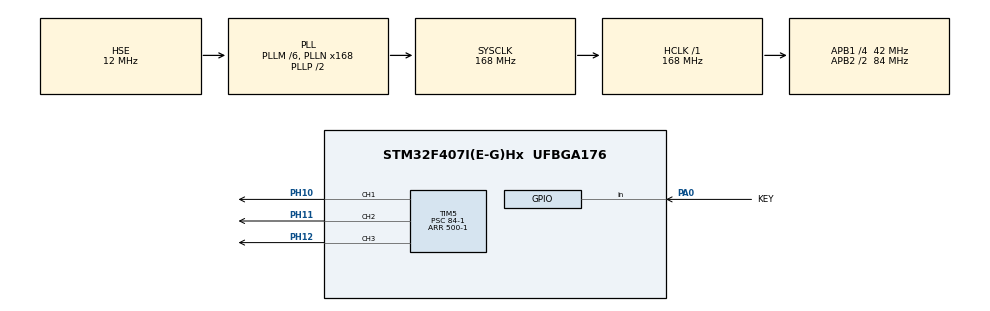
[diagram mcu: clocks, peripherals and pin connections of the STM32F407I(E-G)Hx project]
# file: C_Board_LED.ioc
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FREERTOS.Tasks01=LedTask,24,128,StartLedTask,Default,NULL,Dynamic,NULL,NULL
Mcu.Family=STM32F4
Mcu.Name=STM32F407I(E-G)Hx
Mcu.Package=UFBGA176
NVIC.PriorityGroup=NVIC_PRIORITYGROUP_4
NVIC.TIM4_IRQn=true\:15\:0\:false\:false\:true\:false\:false\:true\:true
NVIC.TimeBase=TIM4_IRQn
NVIC.TimeBaseIP=TIM4
PA0-WKUP.GPIO_Label=KEY
PA0-WKUP.GPIO_PuPd=GPIO_NOPULL
PA0-WKUP.Signal=GPIO_Input
PA13.Mode=Serial_Wire
PA13.Signal=SYS_JTMS-SWDIO
PA14.Mode=Serial_Wire
PA14.Signal=SYS_JTCK-SWCLK
PH0-OSC_IN.Mode=HSE-External-Oscillator
PH0-OSC_IN.Signal=RCC_OSC_IN
PH1-OSC_OUT.Mode=HSE-External-Oscillator
PH1-OSC_OUT.Signal=RCC_OSC_OUT
PH10.Signal=S_TIM5_CH1
PH11.Signal=S_TIM5_CH2
PH12.Signal=S_TIM5_CH3
ProjectManager.HeapSize=0x200
ProjectManager.StackSize=0x400
ProjectManager.TargetToolchain=CMake
RCC.48MHZClocksFreq_Value=84000000
RCC.AHBFreq_Value=168000000
RCC.APB1CLKDivider=RCC_HCLK_DIV4
RCC.APB1Freq_Value=42000000
RCC.APB1TimFreq_Value=84000000
RCC.APB2CLKDivider=RCC_HCLK_DIV2
RCC.APB2Freq_Value=84000000
RCC.APB2TimFreq_Value=168000000
RCC.CortexFreq_Value=168000000
RCC.HCLKFreq_Value=168000000
RCC.HSE_VALUE=12000000
RCC.HSI_VALUE=16000000
RCC.LSE_VALUE=32768
RCC.PLLM=6
RCC.PLLN=168
RCC.PLLSourceVirtual=RCC_PLLSOURCE_HSE
RCC.SYSCLKFreq_VALUE=168000000
RCC.SYSCLKSource=RCC_SYSCLKSOURCE_PLLCLK
RCC.VCOOutputFreq_Value=336000000
SH.S_TIM5_CH1.0=TIM5_CH1,PWM Generation1 CH1
SH.S_TIM5_CH2.0=TIM5_CH2,PWM Generation2 CH2
SH.S_TIM5_CH3.0=TIM5_CH3,PWM Generation3 CH3
TIM5.Channel-PWM\ Generation1\ CH1=TIM_CHANNEL_1
TIM5.Channel-PWM\ Generation2\ CH2=TIM_CHANNEL_2
TIM5.Channel-PWM\ Generation3\ CH3=TIM_CHANNEL_3
TIM5.Period=500-1
TIM5.Prescaler=84-1
TIM5.Pulse-PWM\ Generation1\ CH1=250
TIM5.Pulse-PWM\ Generation2\ CH2=250
TIM5.Pulse-PWM\ Generation3\ CH3=250
VP_FREERTOS_VS_CMSIS_V2.Mode=CMSIS_V2
VP_SYS_VS_tim4.Mode=TIM4
VP_TIM5_VS_ClockSourceINT.Mode=Internal
board=custom

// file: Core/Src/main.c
/* USER CODE BEGIN Header */
/**
  ******************************************************************************
  * @file           : main.c
  * @brief          : Main program body
  ******************************************************************************
  * @attention
  *
  * Copyright (c) 2026 STMicroelectronics.
  * All rights reserved.
  *
  * This software is licensed under terms that can be found in the LICENSE file
  * in the root directory of this software component.
  * If no LICENSE file comes with this software, it is provided AS-IS.
  *
  ******************************************************************************
  */
/* USER CODE END Header */
#include "main.h"
#include "cmsis_os.h"
#include "tim.h"
#include "gpio.h"

void SystemClock_Config(void);
void MX_FREERTOS_Init(void);

int main(void)
{

  /* MCU Configuration--------------------------------------------------------*/

  /* Reset of all peripherals, Initializes the Flash interface and the Systick. */
  HAL_Init();

  /* Configure the system clock */
  SystemClock_Config();

  /* Initialize all configured peripherals */
  MX_GPIO_Init();
  MX_TIM5_Init();

  /* Init scheduler */
  osKernelInitialize();  /* Call init function for freertos objects (in cmsis_os2.c) */
  MX_FREERTOS_Init();

  /* Start scheduler */
  osKernelStart();

  /* We should never get here as control is now taken by the scheduler */

  /* Infinite loop */
  while (1)
  {

  }
}

void SystemClock_Config(void)
{
  RCC_OscInitTypeDef RCC_OscInitStruct = {0};
  RCC_ClkInitTypeDef RCC_ClkInitStruct = {0};

  /** Configure the main internal regulator output voltage
  */
  __HAL_RCC_PWR_CLK_ENABLE();
  __HAL_PWR_VOLTAGESCALING_CONFIG(PWR_REGULATOR_VOLTAGE_SCALE1);

  /** Initializes the RCC Oscillators according to the specified parameters
  * in the RCC_OscInitTypeDef structure.
  */
  RCC_OscInitStruct.OscillatorType = RCC_OSCILLATORTYPE_HSE;
  RCC_OscInitStruct.HSEState = RCC_HSE_ON;
  RCC_OscInitStruct.PLL.PLLState = RCC_PLL_ON;
  RCC_OscInitStruct.PLL.PLLSource = RCC_PLLSOURCE_HSE;
  RCC_OscInitStruct.PLL.PLLM = 6;
  RCC_OscInitStruct.PLL.PLLN = 168;
  RCC_OscInitStruct.PLL.PLLP = RCC_PLLP_DIV2;
  RCC_OscInitStruct.PLL.PLLQ = 4;
  if (HAL_RCC_OscConfig(&RCC_OscInitStruct) != HAL_OK)
  {
    Error_Handler();
  }

  /** Initializes the CPU, AHB and APB buses clocks
  */
  RCC_ClkInitStruct.ClockType = RCC_CLOCKTYPE_HCLK|RCC_CLOCKTYPE_SYSCLK
                              |RCC_CLOCKTYPE_PCLK1|RCC_CLOCKTYPE_PCLK2;
  RCC_ClkInitStruct.SYSCLKSource = RCC_SYSCLKSOURCE_PLLCLK;
  RCC_ClkInitStruct.AHBCLKDivider = RCC_SYSCLK_DIV1;
  RCC_ClkInitStruct.APB1CLKDivider = RCC_HCLK_DIV4;
  RCC_ClkInitStruct.APB2CLKDivider = RCC_HCLK_DIV2;

  if (HAL_RCC_ClockConfig(&RCC_ClkInitStruct, FLASH_LATENCY_5) != HAL_OK)
  {
    Error_Handler();
  }
}

void HAL_TIM_PeriodElapsedCallback(TIM_HandleTypeDef *htim)
{
  if (htim->Instance == TIM4)
  {
    HAL_IncTick();
  }
}

void Error_Handler(void)
{
  __disable_irq();
  while (1)
  {
  }
}

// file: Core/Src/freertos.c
/* USER CODE BEGIN Header */
/**
  ******************************************************************************
  * File Name          : freertos.c
  * Description        : Code for freertos applications
  ******************************************************************************
  * @attention
  *
  * Copyright (c) 2026 STMicroelectronics.
  * All rights reserved.
  *
  * This software is licensed under terms that can be found in the LICENSE file
  * in the root directory of this software component.
  * If no LICENSE file comes with this software, it is provided AS-IS.
  *
  ******************************************************************************
  */
/* USER CODE END Header */

#include "FreeRTOS.h"
#include "task.h"
#include "main.h"
#include "cmsis_os.h"
#include "tim.h"

/* Definitions for LedTask */
osThreadId_t LedTaskHandle;
const osThreadAttr_t LedTask_attributes = {
  .name = "LedTask",
  .stack_size = 128 * 4,
  .priority = (osPriority_t) osPriorityNormal,
};

void StartLedTask(void *argument);

void MX_FREERTOS_Init(void); /* (MISRA C 2004 rule 8.1) */

void MX_FREERTOS_Init(void) {

  /* Create the thread(s) */
  /* creation of LedTask */
  LedTaskHandle = osThreadNew(StartLedTask, NULL, &LedTask_attributes);

}

void StartLedTask(void *argument)
{
  /* USER CODE BEGIN StartLedTask */
  HAL_TIM_PWM_Start(&htim5, TIM_CHANNEL_1);
  HAL_TIM_PWM_Start(&htim5, TIM_CHANNEL_2);
  HAL_TIM_PWM_Start(&htim5, TIM_CHANNEL_3);
  /* Infinite loop */
  for(;;)
  {
    for (uint16_t i = 0; i <500; i+=10)
    {
      __HAL_TIM_SET_COMPARE(&htim5, TIM_CHANNEL_1, i);
      __HAL_TIM_SET_COMPARE(&htim5, TIM_CHANNEL_2, 500 - i);
      __HAL_TIM_SET_COMPARE(&htim5, TIM_CHANNEL_3, i / 2);
      osDelay(10);
    }
    for (uint16_t i = 500; i > 0; i-=10)
    {
      __HAL_TIM_SET_COMPARE(&htim5, TIM_CHANNEL_1, i);
      __HAL_TIM_SET_COMPARE(&htim5, TIM_CHANNEL_2, 500 - i);
      __HAL_TIM_SET_COMPARE(&htim5, TIM_CHANNEL_3, i / 2);
      osDelay(10);
    }
  }
  /* USER CODE END StartLedTask */
}

/* Private application code ------------------------------------------------__*/
